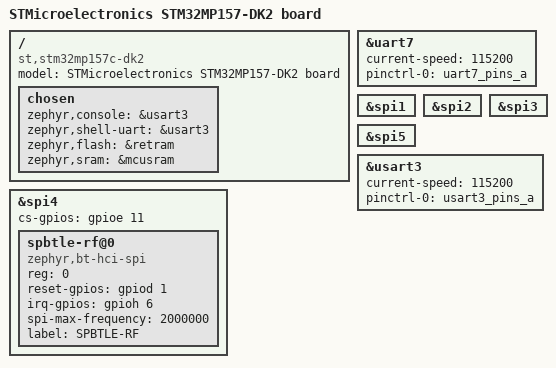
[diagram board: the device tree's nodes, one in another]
/*
 * Copyright (c) 2019 STMicroelectronics
 *
 * SPDX-License-Identifier: Apache-2.0
 */

/dts-v1/;
#include <st/mp1/stm32mp157.dtsi>

/ {
	model = "STMicroelectronics STM32MP157-DK2  board";
	compatible = "st,stm32mp157c-dk2", "st,stm32mp15";
	chosen {
		zephyr,console = &usart3;
		zephyr,shell-uart = &usart3;
		zephyr,flash = &retram;
		zephyr,sram = &mcusram;
	};
};

arduino_serial: &uart7 {};
arduino_spi: &spi4 {};

&spi1 {
	status = "ok";
};

&spi2 {
	status = "ok";
};

&spi3 {
	status = "ok";
};

&spi4 {
	status = "ok";
	cs-gpios = <&gpioe 11 0>;

	spbtle-rf@0 {
		compatible = "zephyr,bt-hci-spi";
		reg = <0>;
		reset-gpios = <&gpiod 1 0>;
		irq-gpios = <&gpioh 6 0>;
		spi-max-frequency = <2000000>;
		label = "SPBTLE-RF";
	};
};

&spi5 {
	status = "ok";
};

&usart3 {
	current-speed = <115200>;
	pinctrl-0 = <&usart3_pins_a>;
	pinctrl-names = "default";
	status = "ok";
};

&uart7 {
	current-speed = <115200>;
	pinctrl-0 = <&uart7_pins_a>;
	pinctrl-names = "default";
	status = "ok";
};
